# LCD_B_1 register map
Vendor: Texas Instruments
Peripheral module from a debugger description file (folder msp430).
Registers are 8-bit, access not given, no defined reset value unless marked. A register's access mark holds for its fields unless they carry their own. Offsets are as the file gives them; lines under a group give offsets from that group; [hi:lo] are bit positions; {n}, {i} and the like mark numbered series; 'fields as' and 'values as' point back to an identical list; <NAME> marks a mode.

## LCD_B
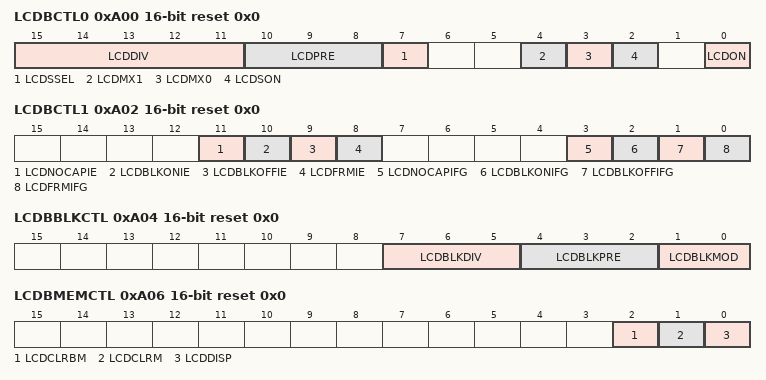
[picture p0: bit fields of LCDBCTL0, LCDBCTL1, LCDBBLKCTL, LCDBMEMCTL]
0xA00 LCDBCTL0 16-bit rw reset 0x0 — LCD_B Control Register 0
  [15:11] LCDDIV — LCD_B LCD frequency divider Bit: 0
    {v}=LCD_B LCD frequency divider: /{v+1} (v=0..31)
  [10:8] LCDPRE — LCD_B LCD frequency pre-scaler Bit: 0
    0=LCD_B LCD frequency pre-scaler: /1; 1=LCD_B LCD frequency pre-scaler: /2; 2=LCD_B LCD frequency pre-scaler: /4; 3=LCD_B LCD frequency pre-scaler: /8; 4=LCD_B LCD frequency pre-scaler: /16; 5=LCD_B LCD frequency pre-scaler: /32
  [7] LCDSSEL — LCD_B Clock Select
  [4] LCDMX1 — LCD_B Mux Rate Bit: 1
  [3] LCDMX0 — LCD_B Mux Rate Bit: 0
  [2] LCDSON — LCD_B LCD Segments On
  [0] LCDON — LCD_B LCD On
0xA02 LCDBCTL1 16-bit rw reset 0x0 — LCD_B Control Register 1
  [11] LCDNOCAPIE — LCD_B No cpacitance connected interrupt enable
  [10] LCDBLKONIE — LCD_B LCD blinking on interrupt flag
  [9] LCDBLKOFFIE — LCD_B LCD blinking off interrupt flag
  [8] LCDFRMIE — LCD_B LCD frame interrupt enable
  [3] LCDNOCAPIFG — LCD_B No cpacitance connected interrupt flag
  [2] LCDBLKONIFG — LCD_B LCD blinking on interrupt flag
  [1] LCDBLKOFFIFG — LCD_B LCD blinking off interrupt flag
  [0] LCDFRMIFG — LCD_B LCD frame interrupt flag
0xA04 LCDBBLKCTL 16-bit rw reset 0x0 — LCD_B blinking control register
  [7:5] LCDBLKDIV — LCD_B Clock divider for blinking frequency Bit: 0
    {v}=LCD_B Clock divider for blinking frequency: {v} (v=0..7)
  [4:2] LCDBLKPRE — LCD_B Clock pre-scaler for blinking frequency Bit: 0
    {v}=LCD_B Clock pre-scaler for blinking frequency: {v} (v=0..7)
  [1:0] LCDBLKMOD — LCD_B Blinking mode Bit: 0
    0=LCD_B Blinking mode: Off; 1=LCD_B Blinking mode: Individual; 2=LCD_B Blinking mode: All; 3=LCD_B Blinking mode: Switching
0xA06 LCDBMEMCTL 16-bit rw reset 0x0 — LCD_B memory control register
  [2] LCDCLRBM — LCD_B Clear LCD blinking memory
  [1] LCDCLRM — LCD_B Clear LCD memory
  [0] LCDDISP — LCD_B LCD memory registers for display
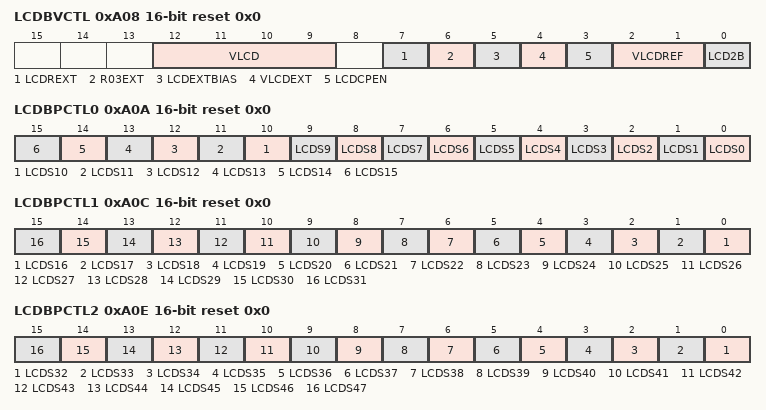
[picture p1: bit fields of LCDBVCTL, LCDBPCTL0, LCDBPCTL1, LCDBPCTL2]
0xA08 LCDBVCTL 16-bit rw reset 0x0 — LCD_B Voltage Control Register
  [12:9] VLCD — VLCD select: 0
    0=Charge pump disabled; 1=VLCD = 2.60V; 2=VLCD = 2.66V; 3=VLCD = 2.72V; 4=VLCD = 2.78V; 5=VLCD = 2.84V; 6=VLCD = 2.90V; 7=VLCD = 2.96V; 8=VLCD = 3.02V; 9=VLCD = 3.08V; 10=VLCD = 3.14V; 11=VLCD = 3.20V; 12=VLCD = 3.26V; 13=VLCD = 3.32V; 14=VLCD = 3.38V; 15=VLCD = 3.44V
  [7] LCDREXT — Selects external connection for lowest LCD voltage.
  [6] R03EXT — Selects external connections for LCD mid voltages.
  [5] LCDEXTBIAS — V2 - V4 voltage select.
  [4] VLCDEXT — Select external source for VLCD.
  [3] LCDCPEN — LCD Voltage Charge Pump Enable.
  [2:1] VLCDREF — Selects reference voltage for regulated charge pump: 0
    0=Internal; 1=External
  [0] LCD2B — Selects 1/2 bias.
0xA0A LCDBPCTL0 16-bit rw reset 0x0 — LCD_B Port Control Register 0
  [n] LCDS{n} (n=0..15) — LCD Segment {n} enable.
0xA0C LCDBPCTL1 16-bit rw reset 0x0 — LCD_B Port Control Register 1
  [n-16] LCDS{n} (n=16..31) — LCD Segment {n} enable.
0xA0E LCDBPCTL2 16-bit rw reset 0x0 — LCD_B Port Control Register 2
  [n-32] LCDS{n} (n=32..47) — LCD Segment {n} enable.
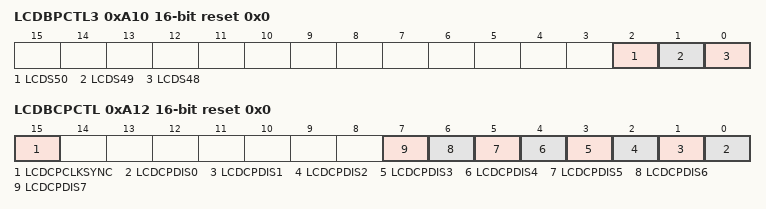
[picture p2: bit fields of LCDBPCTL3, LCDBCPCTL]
0xA10 LCDBPCTL3 16-bit rw reset 0x0 — LCD_B Port Control Register 3
  [2] LCDS50 — LCD Segment 50 enable.
  [1] LCDS49 — LCD Segment 49 enable.
  [0] LCDS48 — LCD Segment 48 enable.
0xA12 LCDBCPCTL 16-bit rw reset 0x0 — LCD_B Charge Pump Control Register 3
  [15] LCDCPCLKSYNC — LCD charge pump clock synchronization
  [n] LCDCPDIS{n} (n=0..7) — LCD charge pump disable
0xA1E LCDBIV 16-bit — LCD_B Interrupt Vector Register
{0xA1F+i} LCDM{i} (i=1..24) — LCD Memory {i}
{0xA3F+i} LCDBM{i} (i=1..24) — LCD Blinking Memory {i}
